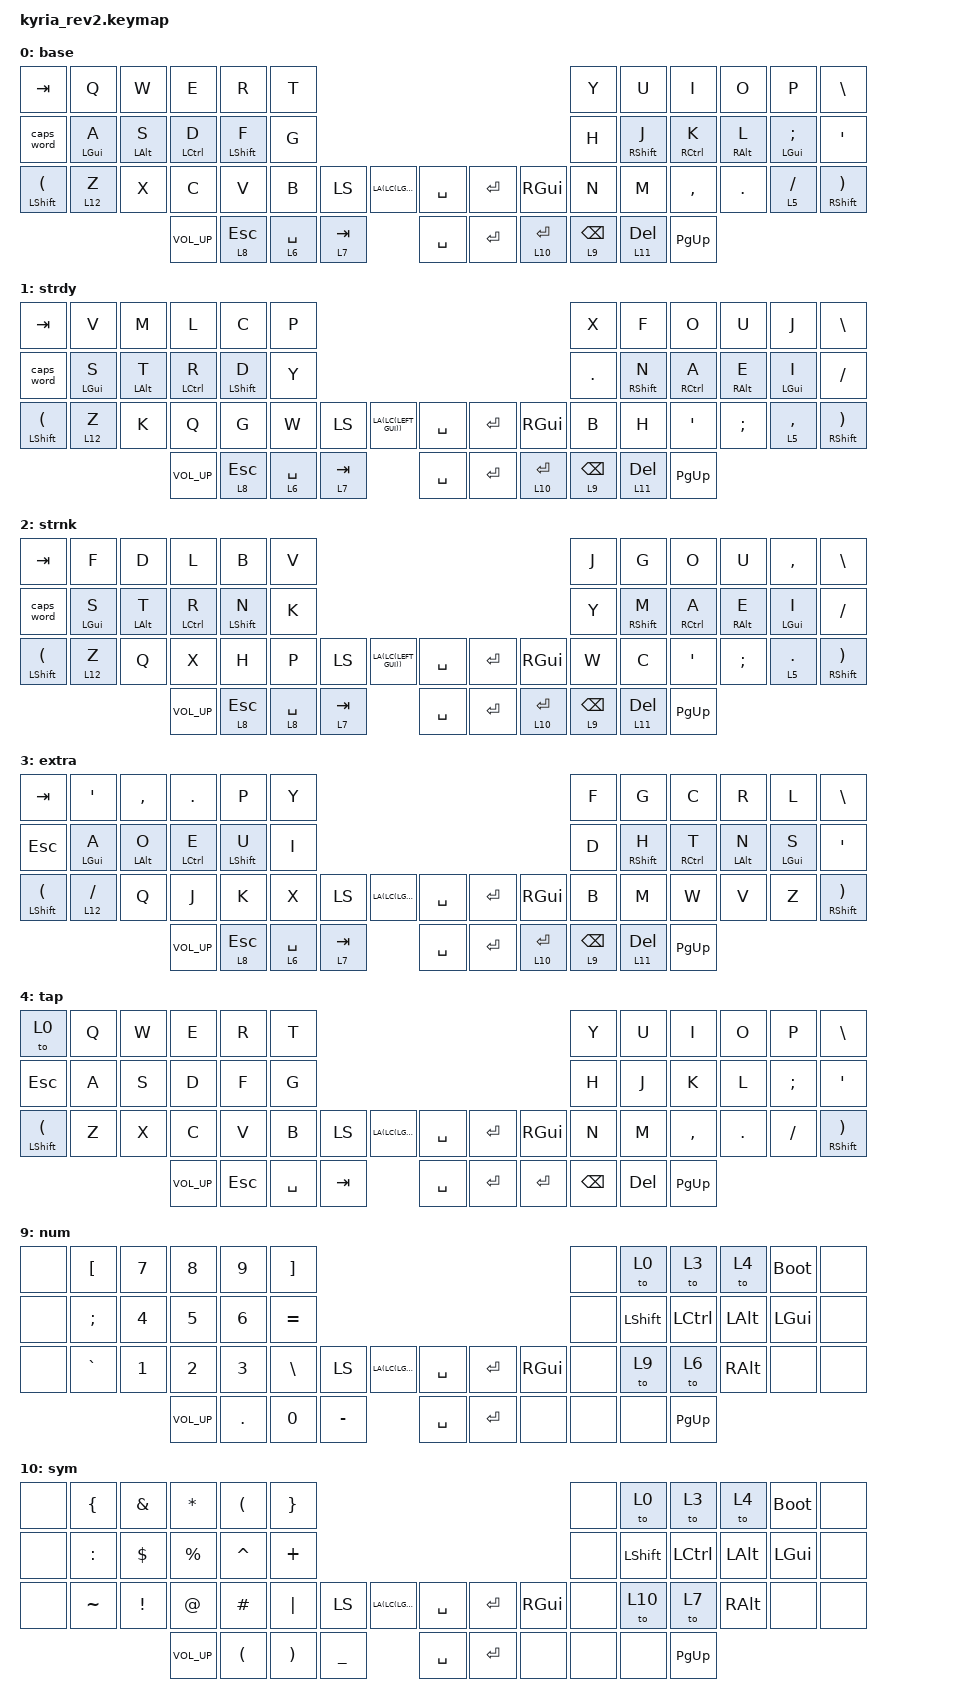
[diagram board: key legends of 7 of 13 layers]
/*
 * Copyright (c) 2020 The ZMK Contributors
 *
 * SPDX-License-Identifier: MIT
 */

#include <dt-bindings/zmk/mouse.h>
#include <behaviors.dtsi>
#include <dt-bindings/zmk/bt.h>
#include <dt-bindings/zmk/ext_power.h>
#include <dt-bindings/zmk/keys.h>
#include <dt-bindings/zmk/outputs.h>
#include <dt-bindings/zmk/pointing.h>

#define DEFAULT 0
#define RAISE 1
#define LOWER 2

// General Layout - numbers reflect positon in matrix, for combos
// ------------------------------------------------------------------------------------------------------
// |  0  |  1  |  2  |  3  |  4  |  5  |                            |  6  |  7  |  8  |  9  | 10  | 11  |
// |  12 |  14 |  15 |  16 |  17 |  18 |                            | 19  | 20  | 21  | 22  | 23  | 23  |
// |  24 |  25 |  26 |  27 |  29 |  29 |  30 |  -  |    |  -  | 33  | 34  | 35  | 36  | 37  | 38  | 39  |
//                   |  -  |  41 |  42 |  43 |  44 |    | 45  | 46  | 47  | 48  |  -  |

/ {
    combos {
        compatible = "zmk,combos";

        both-shift-caps-word {
            bindings = <&caps_word>;
            key-positions = <24 39>;
        };
    };

    behaviors {
        u_mt: u_mt {
            compatible = "zmk,behavior-hold-tap";
            label = "home-row mod";
            #binding-cells = <2>;
            flavor = "hold-preferred";
            bindings = <&kp>, <&kp>;

            tapping-term-ms = <200>;
            quick-tap-ms = <200>;
            require-prior-idle-ms = <125>;
        };

        u_lt: u_lt {
            compatible = "zmk,behavior-hold-tap";
            label = "layer hold";
            bindings = <&mo>, <&kp>;

            #binding-cells = <2>;
            tapping-term-ms = <200>;
            flavor = "hold-preferred";
            quick-tap-ms = <200>;
            require-prior-idle-ms = <125>;
        };

        u_bg: u_bg {
            compatible = "zmk,behavior-tap-dance";
            label = "bootloader tap-dance";
            #binding-cells = <0>;
            bindings = <&none>, <&bootloader>;
        };

        u_ep: u_ep {
            compatible = "zmk,behavior-tap-dance";
            label = "U_EP";
            #binding-cells = <0>;
            bindings = <&none>, <&ext_power EP_TOG>;
        };

        u_btca: u_btca {
            compatible = "zmk,behavior-tap-dance";
            label = "clear all bluetooth";
            #binding-cells = <0>;
            bindings = <&none>, <&bt BT_CLR_ALL>;
        };

        u_btcp: u_btcp {
            compatible = "zmk,behavior-tap-dance";
            label = "clear bluetooth pair";
            #binding-cells = <0>;
            bindings = <&none>, <&bt BT_CLR>;
        };

        u_sr: u_sr {
            compatible = "zmk,behavior-tap-dance";
            label = "reset";
            #binding-cells = <0>;
            bindings = <&none>, <&sys_reset>;
        };
    };

    keymap {
        compatible = "zmk,keymap";

        // ----------------------------------------------------------------------------------------------------------------------------------
        // |   ESC   |  Q  |  W  |  E  |   R   |   T   |                                          |   Y   |   U   |  I  |  O  |  P  |    \    |
        // |   TAB   |  A  |  S  |  D  |   F   |   G   |                                          |   H   |   J   |  K  |  L  |  ;  |    '    |
        // | SHIFT/( |  Z  |  X  |  C  |   V   |   B   |  L GUI  |    -    |  |    -    |  R GUI  |   N   |   M   |  ,  |  .  |  /  | SHIFT/) |
        //                       |  -  | L ALT | RAISE |   RET   |  SPACE  |  |  SPACE  |  BSPC   | LOWER | HYPER |  -  |

        base {
            bindings = <
&kp TAB         &kp Q             &kp W         &kp E            &kp R           &kp T                                                                  &kp Y              &kp U          &kp I          &kp O         &kp P            &kp BSLH
&caps_word      &u_mt LEFT_GUI A  &u_mt LALT S  &u_mt LCTRL D    &u_mt LSHFT F   &kp G                                                                  &kp H              &u_mt RSHFT J  &u_mt RCTRL K  &u_mt RALT L  &u_mt LGUI SEMI  &kp SQT
&mt LSHFT LPAR  &u_lt 12 Z        &kp X         &kp C            &kp V           &kp B          &kp LS(LA(LC(LGUI)))  &kp SPACE  &kp RET  &kp RGUI      &kp N              &kp M          &kp COMMA      &kp DOT       &u_lt 5 FSLH     &mt RSHFT RPAR
                                                &kp C_VOLUME_UP  &u_lt 8 ESCAPE  &u_lt 6 SPACE  &u_lt 7 TAB           &kp SPACE  &kp RET  &u_lt 10 RET  &u_lt 9 BACKSPACE  &u_lt 11 DEL   &kp PAGE_UP
            >;

            sensor-bindings =
                <&inc_dec_kp C_VOL_UP C_VOL_DN>,
                <&inc_dec_kp PAGE_UP PAGE_DOWN>;
        };

        strdy {
            bindings = <
&kp TAB                          &kp V             &kp M             &kp L                 &kp C           &kp P                                                                        &kp X              &kp F            &kp O                  &kp U              &kp J           &kp BACKSLASH
&caps_word                       &u_mt LEFT_GUI S  &u_mt LEFT_ALT T  &u_mt LEFT_CONTROL R  &u_mt LSHFT D   &kp Y                                                                        &kp DOT            &u_mt RSHFT N    &u_mt RIGHT_CONTROL A  &u_mt RIGHT_ALT E  &mt LEFT_GUI I  &kp SLASH
&mt LEFT_SHIFT LEFT_PARENTHESIS  &u_lt 12 Z        &kp K             &kp Q                 &kp G           &kp W          &kp LS(LA(LC(LEFT_GUI)))  &kp SPACE  &kp RET  &kp RGUI        &kp B              &kp H            &kp SQT                &kp SEMI           &u_lt 5 COMMA   &mt RSHIFT RIGHT_PARENTHESIS
                                                                     &kp C_VOLUME_UP       &u_lt 8 ESCAPE  &u_lt 6 SPACE  &u_lt 7 TAB               &kp SPACE  &kp RET  &u_lt 10 ENTER  &u_lt 9 BACKSPACE  &u_lt 11 DELETE  &kp PAGE_UP
            >;

            sensor-bindings =
                <&inc_dec_kp C_VOL_UP C_VOL_DN>,
                <&inc_dec_kp PAGE_UP PAGE_DOWN>;
        };

        strnk {
            bindings = <
&kp TAB                     &kp F             &kp D             &kp L            &kp B           &kp V                                                                        &kp J              &kp G            &kp O          &kp U              &kp COMMA         &kp BACKSLASH
&caps_word                  &u_mt LEFT_GUI S  &u_mt LEFT_ALT T  &u_mt LCTRL R    &u_mt LSHFT N   &kp K                                                                        &kp Y              &u_mt RSHFT M    &u_mt RCTRL A  &u_mt RIGHT_ALT E  &u_mt LEFT_GUI I  &kp SLASH
&mt LSHFT LEFT_PARENTHESIS  &u_lt 12 Z        &kp Q             &kp X            &kp H           &kp P          &kp LS(LA(LC(LEFT_GUI)))  &kp SPACE  &kp RET  &kp RGUI        &kp W              &kp C            &kp SQT        &kp SEMI           &u_lt 5 PERIOD    &mt RSHFT RIGHT_PARENTHESIS
                                                                &kp C_VOLUME_UP  &u_lt 8 ESCAPE  &u_lt 8 SPACE  &u_lt 7 TAB               &kp SPACE  &kp RET  &u_lt 10 ENTER  &u_lt 9 BACKSPACE  &u_lt 11 DELETE  &kp PAGE_UP
            >;

            sensor-bindings =
                <&inc_dec_kp C_VOLUME_UP C_VOLUME_DOWN>,
                <&inc_dec_kp PAGE_UP PAGE_DOWN>;
        };

        extra {
            bindings = <
&kp TAB                      &kp SQT         &kp COMMA     &kp DOT          &kp P          &kp Y                                                                  &kp F              &kp G            &kp C          &kp R         &kp L         &kp BACKSLASH
&kp ESC                      &u_mt LGUI A    &u_mt LALT O  &u_mt LCTRL E    &u_mt LSHFT U  &kp I                                                                  &kp D              &u_mt RSHFT H    &u_mt RCTRL T  &u_mt LALT N  &u_mt LGUI S  &kp SQT
&mt LSHIFT LEFT_PARENTHESIS  &u_lt 12 SLASH  &kp Q         &kp J            &kp K          &kp X          &kp LS(LA(LC(LGUI)))  &kp SPACE  &kp RET  &kp RGUI      &kp B              &kp M            &kp W          &kp V         &kp Z         &mt RSHFT RIGHT_PARENTHESIS
                                                           &kp C_VOLUME_UP  &u_lt 8 ESC    &u_lt 6 SPACE  &u_lt 7 TAB           &kp SPACE  &kp RET  &u_lt 10 RET  &u_lt 9 BACKSPACE  &u_lt 11 DELETE  &kp PAGE_UP
            >;

            sensor-bindings =
                <&inc_dec_kp C_VOL_UP C_VOL_DN>,
                <&inc_dec_kp PAGE_UP PAGE_DOWN>;
        };

        tap {
            bindings = <
&to 0                        &kp Q  &kp W  &kp E            &kp R       &kp T                                                          &kp Y          &kp U       &kp I        &kp O    &kp P     &kp BACKSLASH
&kp ESC                      &kp A  &kp S  &kp D            &kp F       &kp G                                                          &kp H          &kp J       &kp K        &kp L    &kp SEMI  &kp SQT
&mt LSHIFT LEFT_PARENTHESIS  &kp Z  &kp X  &kp C            &kp V       &kp B      &kp LS(LA(LC(LGUI)))  &kp SPACE  &kp RET  &kp RGUI  &kp N          &kp M       &kp COMMA    &kp DOT  &kp FSLH  &mt RSHFT RIGHT_PARENTHESIS
                                           &kp C_VOLUME_UP  &kp ESCAPE  &kp SPACE  &kp TAB               &kp SPACE  &kp RET  &kp RET   &kp BACKSPACE  &kp DELETE  &kp PAGE_UP
            >;

            sensor-bindings =
                <&inc_dec_kp C_VOL_UP C_VOL_DN>,
                <&inc_dec_kp PAGE_UP PAGE_DOWN>;
        };

        button_right {
            bindings = <
&none  &kp LG(Z)  &kp LG(X)  &kp LG(C)     &kp LG(V)  &kp LS(LG(Z))                                 &none  &none           &none        &none     &none     &none
&none  &kp LGUI   &kp LALT   &kp LCTRL     &kp LSHFT  &none                                         &none  &kp LEFT_SHIFT  &kp LCTRL    &kp LALT  &kp LGUI  &none
&none  &kp LG(Z)  &kp LG(X)  &kp LG(C)     &kp LG(V)  &kp LG(LS(Z))  &none     &none  &none  &none  &none  &none           &none        &none     &none     &none
                             &kp C_VOL_UP  &mkp MB3   &mkp MB1       &mkp MB2  &none  &none  &none  &none  &none           &kp PAGE_UP
            >;

            sensor-bindings =
                <&inc_dec_kp C_VOL_UP C_VOL_DN>,
                <&inc_dec_kp PAGE_UP PAGE_DOWN>;
        };

        nav {
            bindings = <
&to 0  &to 1     &to 2     &to 3         &to 4      &none                                      &kp LS(LG(Z))  &kp LG(V)      &kp LG(C)    &kp LG(X)  &kp LG(Z)   &none
&none  &kp LGUI  &kp LALT  &kp LCTRL     &kp LSHFT  &none                                      &kp LEFT       &kp DOWN       &kp UP       &kp RIGHT  &caps_word  &none
&u_bg  &none     &kp RALT  &to 9         &to 6      &none  &none  &kp SPACE  &kp RET  &none    &kp HOME       &kp PAGE_DOWN  &kp PAGE_UP  &kp END    &kp INS     &none
                           &kp C_VOL_UP  &none      &none  &none  &kp SPACE  &kp RET  &kp RET  &kp BACKSPACE  &kp DEL        &kp PAGE_UP
            >;

            sensor-bindings =
                <&inc_dec_kp C_VOL_UP C_VOL_DN>,
                <&inc_dec_kp PAGE_UP PAGE_DOWN>;
        };

        mouse {
            bindings = <
&none  &u_bg     &to 4     &to 3         &to 0      &none                                       &none     &none     &none        &none  &none  &none
&none  &kp LGUI  &kp LALT  &kp LCTRL     &kp LSHFT  &none                                       &none     &none     &none        &none  &none  &none
&none  &none     &kp RALT  &to 10        &to 7      &none  &none  &kp SPACE  &kp RET  &none     &none     &none     &none        &none  &none  &none
                           &kp C_VOL_UP  &none      &none  &none  &kp SPACE  &kp RET  &mkp MB2  &mkp MB1  &mkp MB3  &kp PAGE_UP
            >;

            sensor-bindings =
                <&inc_dec_kp C_VOL_UP C_VOL_DN>,
                <&inc_dec_kp PAGE_UP PAGE_DOWN>;
        };

        media {
            bindings = <
&none  &u_bg     &to 4     &to 3         &to 0      &none                                         &none         &u_btca       &u_btcp       &u_sr         &u_bg         &none
&none  &kp LGUI  &kp LALT  &kp LCTRL     &kp LSHFT  &none                                         &kp C_PREV    &kp C_VOL_DN  &kp C_VOL_UP  &kp C_NEXT    &u_ep         &none
&none  &none     &kp RALT  &to 11        &to 8      &none  &none  &kp SPACE  &kp RET  &none       &bt BT_SEL 0  &bt BT_SEL 1  &bt BT_SEL 2  &bt BT_SEL 3  &out OUT_TOG  &none
                           &kp C_VOL_UP  &none      &none  &none  &kp SPACE  &kp RET  &kp C_STOP  &kp C_PP      &kp C_MUTE    &kp PAGE_UP
            >;

            sensor-bindings =
                <&inc_dec_kp C_VOL_UP C_VOL_DN>,
                <&inc_dec_kp PAGE_UP PAGE_DOWN>;
        };

        num {
            bindings = <
&none  &kp LBKT   &kp N7  &kp N8        &kp N9   &kp RBKT                                                       &none  &to 0      &to 3        &to 4     &bootloader  &none
&none  &kp SEMI   &kp N4  &kp N5        &kp N6   &kp EQUAL                                                      &none  &kp LSHFT  &kp LCTRL    &kp LALT  &kp LGUI     &none
&none  &kp GRAVE  &kp N1  &kp N2        &kp N3   &kp BSLH   &kp LS(LA(LC(LGUI)))  &kp SPACE  &kp RET  &kp RGUI  &none  &to 9      &to 6        &kp RALT  &none        &none
                          &kp C_VOL_UP  &kp DOT  &kp N0     &kp MINUS             &kp SPACE  &kp RET  &none     &none  &none      &kp PAGE_UP
            >;

            sensor-bindings =
                <&inc_dec_kp C_VOL_UP C_VOL_DN>,
                <&inc_dec_kp PAGE_UP PAGE_DOWN>;
        };

        sym {
            bindings = <
&none  &kp LBRC   &kp AMPS  &kp ASTRK     &kp LPAR   &kp RBRC                                                      &none  &to 0      &to 3        &to 4     &bootloader  &none
&none  &kp COLON  &kp DLLR  &kp PRCNT     &kp CARET  &kp PLUS                                                      &none  &kp LSHFT  &kp LCTRL    &kp LALT  &kp LGUI     &none
&none  &kp TILDE  &kp EXCL  &kp AT        &kp HASH   &kp PIPE  &kp LS(LA(LC(LGUI)))  &kp SPACE  &kp RET  &kp RGUI  &none  &to 10     &to 7        &kp RALT  &none        &none
                            &kp C_VOL_UP  &kp LPAR   &kp RPAR  &kp UNDER             &kp SPACE  &kp RET  &none     &none  &none      &kp PAGE_UP
            >;

            sensor-bindings =
                <&inc_dec_kp C_VOL_UP C_VOL_DN>,
                <&inc_dec_kp PAGE_UP PAGE_DOWN>;
        };

        fun {
            bindings = <
&none  &kp F12  &kp F7  &kp F8        &kp F9         &kp PSCRN                                            &none  &to 0      &to 3        &to 4     &bootloader  &none
&none  &kp F11  &kp F4  &kp F5        &kp F6         &kp SLCK                                             &none  &kp LSHFT  &kp LCTRL    &kp LALT  &kp LGUI     &none
&none  &kp F10  &kp F1  &kp F2        &kp F3         &kp PAUSE_BREAK  &none    &kp SPACE  &kp RET  &none  &none  &to 11     &to 8        &kp RALT  &none        &none
                        &kp C_VOL_UP  &kp LA(SPACE)  &kp SPACE        &kp TAB  &kp SPACE  &kp RET  &none  &none  &none      &kp PAGE_UP
            >;

            sensor-bindings =
                <&inc_dec_kp C_VOL_UP C_VOL_DN>,
                <&inc_dec_kp PAGE_UP PAGE_DOWN>;
        };

        button_left {
            bindings = <
&none  &none         &none         &none         &none      &none                                       &kp LS(LG(Z))  &kp LG(V)       &kp LG(C)    &kp LG(X)  &kp LG(Z)  &none
&none  &kp LEFT_GUI  &kp LEFT_ALT  &kp LCTRL     &kp LSHFT  &none                                       &none          &kp LEFT_SHIFT  &kp LCTRL    &kp LALT   &kp LGUI   &none
&none  &none         &none         &none         &none      &none  &none  &kp SPACE  &kp RET  &none     &kp LS(LG(Z))  &kp LG(V)       &kp LG(C)    &kp LG(X)  &kp LG(Z)  &none
                                   &kp C_VOL_UP  &none      &none  &none  &kp SPACE  &kp RET  &mkp MB2  &mkp MB1       &mkp MB3        &kp PAGE_UP
            >;

            sensor-bindings =
                <&inc_dec_kp C_VOL_UP C_VOL_DN>,
                <&inc_dec_kp PAGE_UP PAGE_DOWN>;
        };
    };
};
